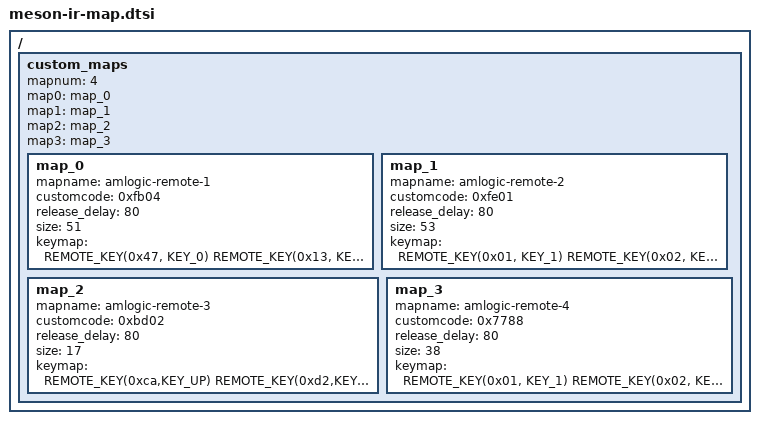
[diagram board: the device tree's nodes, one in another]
// SPDX-License-Identifier: (GPL-2.0+ OR MIT)
/*
 * Copyright (c) 2019 Amlogic, Inc. All rights reserved.
 */

/ {

	custom_maps: custom_maps {
		mapnum = <4>;
		map0 = <&map_0>;
		map1 = <&map_1>;
		map2 = <&map_2>;
		map3 = <&map_3>;
		map_0: map_0{
			mapname = "amlogic-remote-1";
			customcode = <0xfb04>;
			release_delay = <80>;
			size  = <51>;   /*keymap size*/
			keymap = <REMOTE_KEY(0x47, KEY_0)
				REMOTE_KEY(0x13, KEY_1)
				REMOTE_KEY(0x10, KEY_2)
				REMOTE_KEY(0x11, KEY_3)
				REMOTE_KEY(0x0F, KEY_4)
				REMOTE_KEY(0x0C, KEY_5)
				REMOTE_KEY(0x0D, KEY_6)
				REMOTE_KEY(0x0B, KEY_7)
				REMOTE_KEY(0x08, KEY_8)
				REMOTE_KEY(0x09, KEY_9)
				REMOTE_KEY(0x5C, KEY_RIGHTCTRL)
				REMOTE_KEY(0x51, KEY_F3)
				REMOTE_KEY(0x50, KEY_F4)
				REMOTE_KEY(0x40, KEY_F5)
				REMOTE_KEY(0x4d, KEY_F6)
				REMOTE_KEY(0x43, KEY_F7)
				REMOTE_KEY(0x17, KEY_F8)
				REMOTE_KEY(0x00, KEY_F9)
				REMOTE_KEY(0x01, KEY_F10)
				REMOTE_KEY(0x16, KEY_F11)
				REMOTE_KEY(0x49, KEY_BACKSPACE)
				REMOTE_KEY(0x06, KEY_PROPS)
				REMOTE_KEY(0x14, KEY_UNDO)
				REMOTE_KEY(0x44, KEY_UP)
				REMOTE_KEY(0x1D, KEY_DOWN)
				REMOTE_KEY(0x1C, KEY_LEFT)
				REMOTE_KEY(0x48, KEY_RIGHT)
				REMOTE_KEY(0x53, KEY_LEFTMETA)
				REMOTE_KEY(0x45, KEY_PAGEUP)
				REMOTE_KEY(0x19, KEY_PAGEDOWN)
				REMOTE_KEY(0x52, KEY_PAUSE)
				REMOTE_KEY(0x05, KEY_HANGEUL)
				REMOTE_KEY(0x59, KEY_HANJA)
				REMOTE_KEY(0x1b, KEY_SCALE)
				REMOTE_KEY(0x04, KEY_KPCOMMA)
				REMOTE_KEY(0x1A, KEY_POWER)
				REMOTE_KEY(0x0A, KEY_TAB)
				REMOTE_KEY(0x0e, KEY_MUTE)
				REMOTE_KEY(0x1F, KEY_HOME)
				REMOTE_KEY(0x1e, KEY_FRONT)
				REMOTE_KEY(0x07, KEY_COPY)
				REMOTE_KEY(0x12, KEY_OPEN)
				REMOTE_KEY(0x54, KEY_PASTE)
				REMOTE_KEY(0x02, KEY_FIND)
				REMOTE_KEY(0x4f, KEY_A)
				REMOTE_KEY(0x42, KEY_B)
				REMOTE_KEY(0x5d, KEY_C)
				REMOTE_KEY(0x4c, KEY_D)
				REMOTE_KEY(0x58, KEY_CUT)
				REMOTE_KEY(0x15, KEY_SEARCH)
				REMOTE_KEY(0x55, KEY_CALC)>;
		};

		map_1: map_1{
			mapname = "amlogic-remote-2";
			customcode = <0xfe01>;
			release_delay = <80>;
			size  = <53>;
			keymap = <REMOTE_KEY(0x01, KEY_1)
				REMOTE_KEY(0x02, KEY_2)
				REMOTE_KEY(0x03, KEY_3)
				REMOTE_KEY(0x04, KEY_4)
				REMOTE_KEY(0x05, KEY_5)
				REMOTE_KEY(0x06, KEY_6)
				REMOTE_KEY(0x07, KEY_7)
				REMOTE_KEY(0x08, KEY_8)
				REMOTE_KEY(0x09, KEY_9)
				REMOTE_KEY(0x0a, KEY_0)
				REMOTE_KEY(0x1F, KEY_FN_F1)
				REMOTE_KEY(0x15, KEY_MENU)
				REMOTE_KEY(0x16, KEY_TAB)
				REMOTE_KEY(0x0c, KEY_CHANNELUP)
				REMOTE_KEY(0x0d, KEY_CHANNELDOWN)
				REMOTE_KEY(0x0e, KEY_VOLUMEUP)
				REMOTE_KEY(0x0f, KEY_VOLUMEDOWN)
				REMOTE_KEY(0x11, KEY_HOME)
				REMOTE_KEY(0x1c, KEY_RIGHT)
				REMOTE_KEY(0x1b, KEY_LEFT)
				REMOTE_KEY(0x19, KEY_UP)
				REMOTE_KEY(0x1a, KEY_DOWN)
				REMOTE_KEY(0x1d, KEY_ENTER)
				REMOTE_KEY(0x17, KEY_MUTE)
				REMOTE_KEY(0x49, KEY_FINANCE)
				REMOTE_KEY(0x43, KEY_BACK)
				REMOTE_KEY(0x12, KEY_FN_F4)
				REMOTE_KEY(0x14, KEY_FN_F5)
				REMOTE_KEY(0x18, KEY_FN_F6)
				REMOTE_KEY(0x59, KEY_INFO)
				REMOTE_KEY(0x5a, KEY_STOPCD)
				REMOTE_KEY(0x10, KEY_POWER)
				REMOTE_KEY(0x42, KEY_PREVIOUSSONG)
				REMOTE_KEY(0x44, KEY_NEXTSONG)
				REMOTE_KEY(0x1e, KEY_REWIND)
				REMOTE_KEY(0x4b, KEY_FASTFORWARD)
				REMOTE_KEY(0x58, KEY_PLAYPAUSE)
				REMOTE_KEY(0x46, KEY_PROPS)
				REMOTE_KEY(0x40, KEY_UNDO)
				REMOTE_KEY(0x38, KEY_SCROLLLOCK)
				REMOTE_KEY(0x57, KEY_FN)
				REMOTE_KEY(0x5b, KEY_FN_ESC)
				REMOTE_KEY(0x54, KEY_RED)
				REMOTE_KEY(0x4c, KEY_GREEN)
				REMOTE_KEY(0x4e, KEY_YELLOW)
				REMOTE_KEY(0x55, KEY_BLUE)
				REMOTE_KEY(0x53, KEY_BLUETOOTH)
				REMOTE_KEY(0x52, KEY_LIST)
				REMOTE_KEY(0x39, KEY_CAMERA)
				REMOTE_KEY(0x41, KEY_SOUND)
				REMOTE_KEY(0x0b, KEY_QUESTION)
				REMOTE_KEY(0x00, KEY_CHAT)
				REMOTE_KEY(0x13, KEY_SEARCH)>;
		};

		map_2: map_2{
			mapname = "amlogic-remote-3";
			customcode = <0xbd02>;
			release_delay = <80>;
			size  = <17>;
			keymap = <REMOTE_KEY(0xca,KEY_UP)
				REMOTE_KEY(0xd2,KEY_DOWN)
				REMOTE_KEY(0x99,KEY_LEFT)
				REMOTE_KEY(0xc1,KEY_RIGHT)
				REMOTE_KEY(0xce,KEY_RIGHTCTRL)
				REMOTE_KEY(0x45,KEY_POWER)
				REMOTE_KEY(0xc5,KEY_COPY)
				REMOTE_KEY(0x80,KEY_MUTE)
				REMOTE_KEY(0xd0,KEY_TAB)
				REMOTE_KEY(0xd6,KEY_LEFTMETA)
				REMOTE_KEY(0x95,KEY_HOME)
				REMOTE_KEY(0xdd,KEY_PAGEUP)
				REMOTE_KEY(0x8c,KEY_PAGEDOWN)
				REMOTE_KEY(0x89,KEY_UNDO)
				REMOTE_KEY(0x9c,KEY_PROPS)
				REMOTE_KEY(0x9a,KEY_SCALE)
				REMOTE_KEY(0xcd,KEY_KPCOMMA)>;
		};
		map_3: map_3{
			mapname = "amlogic-remote-4";
			customcode = <0x7788>;
			release_delay = <80>;
			size  = <38>;   /*keymap size*/
			keymap = <REMOTE_KEY(0x01, KEY_1)
				REMOTE_KEY(0x02, KEY_2)
				REMOTE_KEY(0x03, KEY_3)
				REMOTE_KEY(0x04, KEY_4)
				REMOTE_KEY(0x05, KEY_5)
				REMOTE_KEY(0x06, KEY_6)
				REMOTE_KEY(0x07, KEY_7)
				REMOTE_KEY(0x08, KEY_8)
				REMOTE_KEY(0x09, KEY_9)
				REMOTE_KEY(0x0A, KEY_0)
				REMOTE_KEY(0x58, KEY_FN_F6)
				REMOTE_KEY(0x29, KEY_INFO)
				REMOTE_KEY(0x74, KEY_BOOKMARKS)
				REMOTE_KEY(0x46, KEY_SEARCH)
				REMOTE_KEY(0x0F, KEY_SETUP)
				REMOTE_KEY(0x15, KEY_UP)
				REMOTE_KEY(0x16, KEY_DOWN)
				REMOTE_KEY(0x17, KEY_LEFT)
				REMOTE_KEY(0x18, KEY_RIGHT)
				REMOTE_KEY(0x19, KEY_ENTER)
				REMOTE_KEY(0x47, KEY_HOME)
				REMOTE_KEY(0x48, KEY_BACK)
				REMOTE_KEY(0x32, KEY_HELP)
				REMOTE_KEY(0x21, KEY_POWER)
				REMOTE_KEY(0x60, KEY_FN_F1)
				REMOTE_KEY(0x25, KEY_MUTE)
				REMOTE_KEY(0x23, KEY_VOLUMEUP)
				REMOTE_KEY(0x24, KEY_VOLUMEDOWN)
				REMOTE_KEY(0x63, KEY_F17)
				REMOTE_KEY(0x64, KEY_F18)
				REMOTE_KEY(0x67, KEY_F19)
				REMOTE_KEY(0x68, KEY_F20)
				REMOTE_KEY(0x33, KEY_CHANNELUP)
				REMOTE_KEY(0x34, KEY_CHANNELDOWN)
				REMOTE_KEY(0x4B, KEY_RED)
				REMOTE_KEY(0x4A, KEY_GREEN)
				REMOTE_KEY(0x49, KEY_YELLOW)
				REMOTE_KEY(0x4C, KEY_BLUE)>;
		};
	};
};
